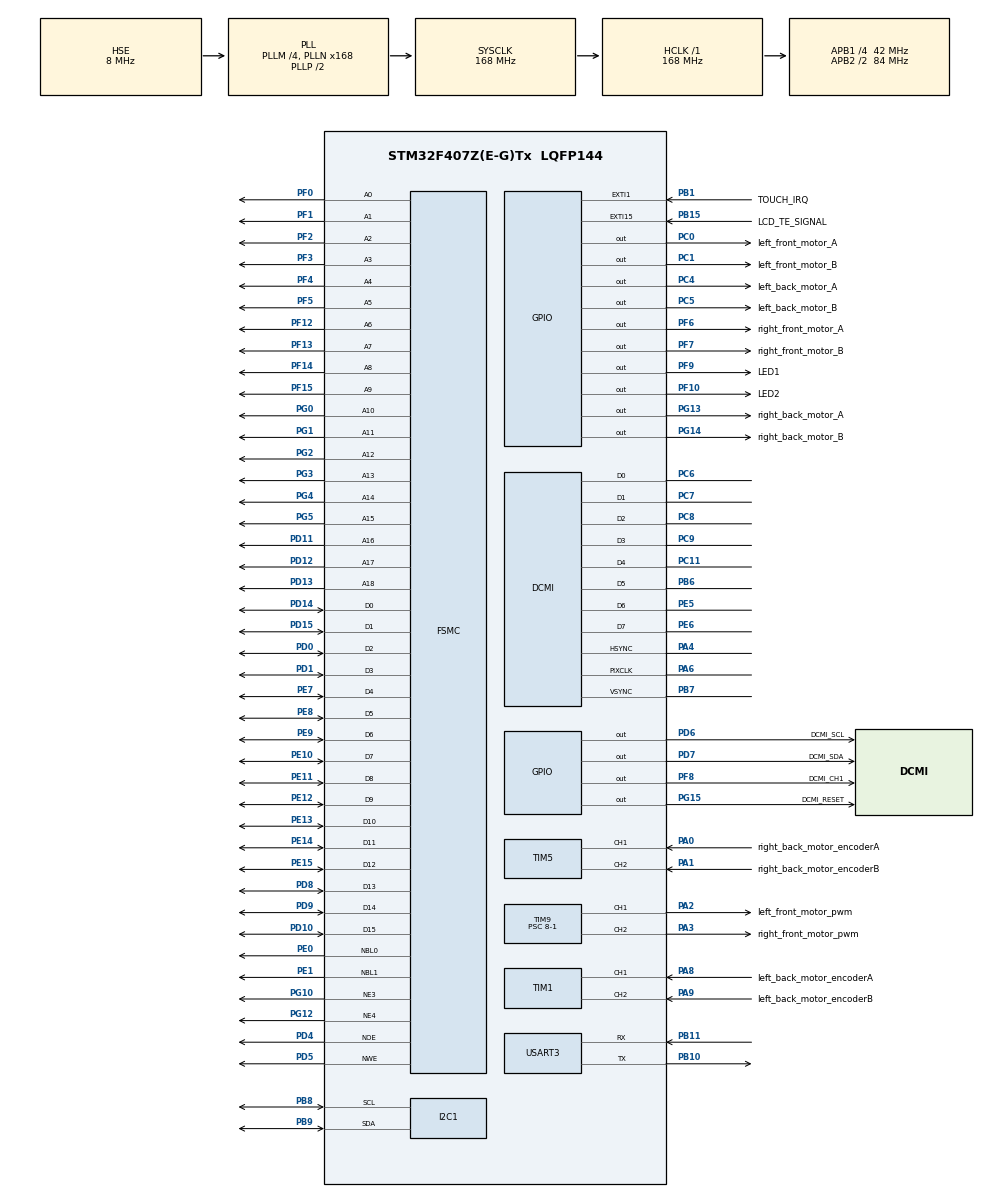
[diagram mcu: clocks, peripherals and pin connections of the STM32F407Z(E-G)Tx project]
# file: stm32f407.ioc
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DCMI.PCKPolarity=DCMI_PCKPOLARITY_RISING
DCMI.VSPolarity=DCMI_VSPOLARITY_LOW
Dma.DCMI.0.Direction=DMA_PERIPH_TO_MEMORY
Dma.DCMI.0.FIFOMode=DMA_FIFOMODE_ENABLE
Dma.DCMI.0.FIFOThreshold=DMA_FIFO_THRESHOLD_FULL
Dma.DCMI.0.Instance=DMA2_Stream1
Dma.DCMI.0.MemBurst=DMA_MBURST_SINGLE
Dma.DCMI.0.MemDataAlignment=DMA_MDATAALIGN_HALFWORD
Dma.DCMI.0.MemInc=DMA_MINC_DISABLE
Dma.DCMI.0.Mode=DMA_CIRCULAR
Dma.DCMI.0.PeriphBurst=DMA_PBURST_SINGLE
Dma.DCMI.0.PeriphDataAlignment=DMA_PDATAALIGN_WORD
Dma.DCMI.0.PeriphInc=DMA_PINC_DISABLE
Dma.DCMI.0.Priority=DMA_PRIORITY_HIGH
Dma.MEMTOMEM.1.Direction=DMA_MEMORY_TO_MEMORY
Dma.MEMTOMEM.1.FIFOMode=DMA_FIFOMODE_ENABLE
Dma.MEMTOMEM.1.FIFOThreshold=DMA_FIFO_THRESHOLD_FULL
Dma.MEMTOMEM.1.Instance=DMA2_Stream0
Dma.MEMTOMEM.1.MemBurst=DMA_MBURST_SINGLE
Dma.MEMTOMEM.1.MemDataAlignment=DMA_MDATAALIGN_HALFWORD
Dma.MEMTOMEM.1.MemInc=DMA_MINC_DISABLE
Dma.MEMTOMEM.1.Mode=DMA_NORMAL
Dma.MEMTOMEM.1.PeriphBurst=DMA_PBURST_SINGLE
Dma.MEMTOMEM.1.PeriphDataAlignment=DMA_PDATAALIGN_HALFWORD
Dma.MEMTOMEM.1.PeriphInc=DMA_PINC_ENABLE
Dma.MEMTOMEM.1.Priority=DMA_PRIORITY_HIGH
Dma.Request0=DCMI
Dma.Request1=MEMTOMEM
FREERTOS.BinarySemaphores01=touchSignal,Static,touchSignalControlBlock
FREERTOS.Queues01=mid_MsgQueue,2,touchDataDef,0,Static,mid_MsgQueueBuffer,mid_MsgQueueControlBlock
FREERTOS.Tasks01=defaultTask,0,128,StartDefaultTask,Default,NULL,Dynamic,NULL,NULL;GUITask,0,4096,StartGUITask,Default,NULL,Static,GUITaskBuffer,GUITaskControlBlock
FREERTOS.configIDLE_SHOULD_YIELD=0
FREERTOS.configUSE_APPLICATION_TASK_TAG=0
FREERTOS.configUSE_NEWLIB_REENTRANT=1
FSMC.AddressSetupTime1=5
FSMC.AddressSetupTime2=2
FSMC.BusTurnAroundDuration1=1
FSMC.BusTurnAroundDuration2=1
FSMC.DataSetupTime1=7
FSMC.DataSetupTime2=2
FSMC.ExtendedMode1=FSMC_EXTENDED_MODE_DISABLE
FSMC.WriteOperation1=FSMC_WRITE_OPERATION_ENABLE
Mcu.Family=STM32F4
Mcu.Name=STM32F407Z(E-G)Tx
Mcu.Package=LQFP144
NVIC.DCMI_IRQn=true\:5\:0\:false\:false\:true\:true\:true\:true
NVIC.DMA2_Stream1_IRQn=true\:5\:0\:false\:false\:true\:true\:false\:true
NVIC.EXTI15_10_IRQn=true\:5\:0\:false\:false\:true\:true\:true\:true
NVIC.EXTI1_IRQn=true\:5\:0\:false\:false\:true\:true\:true\:true
NVIC.PriorityGroup=NVIC_PRIORITYGROUP_4
NVIC.TIM6_DAC_IRQn=true\:15\:0\:false\:false\:true\:false\:false\:true
NVIC.TimeBase=TIM6_DAC_IRQn
NVIC.TimeBaseIP=TIM6
PA0-WKUP.GPIO_Label=right_back_motor_encoderA
PA0-WKUP.GPIO_Speed=GPIO_SPEED_FREQ_VERY_HIGH
PA0-WKUP.Signal=S_TIM5_CH1
PA1.GPIO_Label=right_back_motor_encoderB
PA1.GPIO_Speed=GPIO_SPEED_FREQ_VERY_HIGH
PA1.Signal=S_TIM5_CH2
PA13.Mode=Serial_Wire
PA13.Signal=SYS_JTMS-SWDIO
PA14.Mode=Serial_Wire
PA14.Signal=SYS_JTCK-SWCLK
PA2.GPIO_Label=left_front_motor_pwm
PA2.GPIO_Speed=GPIO_SPEED_FREQ_VERY_HIGH
PA2.Signal=S_TIM9_CH1
PA3.GPIO_Label=right_front_motor_pwm
PA3.GPIO_Speed=GPIO_SPEED_FREQ_VERY_HIGH
PA3.Signal=S_TIM9_CH2
PA4.Mode=Slave_8_bits_External_Synchro
PA4.Signal=DCMI_HSYNC
PA6.Mode=Slave_8_bits_External_Synchro
PA6.Signal=DCMI_PIXCLK
PA8.GPIO_Label=left_back_motor_encoderA
PA8.Signal=S_TIM1_CH1
PA9.GPIO_Label=left_back_motor_encoderB
PA9.Signal=S_TIM1_CH2
PB1.GPIO_Label=TOUCH_IRQ
PB1.GPIO_ModeDefaultEXTI=GPIO_MODE_IT_FALLING
PB1.GPIO_PuPd=GPIO_PULLUP
PB1.Signal=GPXTI1
PB10.Mode=Asynchronous
PB10.Signal=USART3_TX
PB11.Mode=Asynchronous
PB11.Signal=USART3_RX
PB15.GPIO_Label=LCD_TE_SIGNAL
PB15.GPIO_ModeDefaultEXTI=GPIO_MODE_IT_RISING
PB15.Signal=GPXTI15
PB3.Signal=SPI1_SCK
PB4.Signal=SPI1_MISO
PB5.Signal=SPI1_MOSI
PB6.Mode=Slave_8_bits_External_Synchro
PB6.Signal=DCMI_D5
PB7.Mode=Slave_8_bits_External_Synchro
PB7.Signal=DCMI_VSYNC
PB8.GPIO_Pu=GPIO_PULLUP
PB8.Mode=I2C
PB8.Signal=I2C1_SCL
PB9.GPIO_Pu=GPIO_PULLUP
PB9.Mode=I2C
PB9.Signal=I2C1_SDA
PC0.GPIO_Label=left_front_motor_A
PC0.GPIO_Speed=GPIO_SPEED_FREQ_HIGH
PC0.Signal=GPIO_Output
PC1.GPIO_Label=left_front_motor_B
PC1.GPIO_Speed=GPIO_SPEED_FREQ_HIGH
PC1.Signal=GPIO_Output
PC11.Mode=Slave_8_bits_External_Synchro
PC11.Signal=DCMI_D4
PC14-OSC32_IN.Mode=LSE-External-Oscillator
PC14-OSC32_IN.Signal=RCC_OSC32_IN
PC15-OSC32_OUT.Mode=LSE-External-Oscillator
PC15-OSC32_OUT.Signal=RCC_OSC32_OUT
PC4.GPIO_Label=left_back_motor_A
PC4.GPIO_Speed=GPIO_SPEED_FREQ_HIGH
PC4.Signal=GPIO_Output
PC5.GPIO_Label=left_back_motor_B
PC5.GPIO_Speed=GPIO_SPEED_FREQ_HIGH
PC5.Signal=GPIO_Output
PC6.Mode=Slave_8_bits_External_Synchro
PC6.Signal=DCMI_D0
PC7.Mode=Slave_8_bits_External_Synchro
PC7.Signal=DCMI_D1
PC8.Mode=Slave_8_bits_External_Synchro
PC8.Signal=DCMI_D2
PC9.Mode=Slave_8_bits_External_Synchro
PC9.Signal=DCMI_D3
PD0.Signal=FSMC_D2_DA2
PD1.Signal=FSMC_D3_DA3
PD10.Signal=FSMC_D15_DA15
PD11.Signal=FSMC_A16_CLE
PD12.Signal=FSMC_A17_ALE
PD13.Signal=FSMC_A18
PD14.Signal=FSMC_D0_DA0
PD15.Signal=FSMC_D1_DA1
PD4.Signal=FSMC_NOE
PD5.Signal=FSMC_NWE
PD6.GPIO_Label=DCMI_SCL
PD6.GPIO_ModeDefaultOutputPP=GPIO_MODE_OUTPUT_OD
PD6.GPIO_Speed=GPIO_SPEED_FREQ_VERY_HIGH
PD6.PinState=GPIO_PIN_SET
PD6.Signal=GPIO_Output
PD7.GPIO_Label=DCMI_SDA
PD7.GPIO_ModeDefaultOutputPP=GPIO_MODE_OUTPUT_OD
PD7.GPIO_Speed=GPIO_SPEED_FREQ_VERY_HIGH
PD7.PinState=GPIO_PIN_SET
PD7.Signal=GPIO_Output
PD8.Signal=FSMC_D13_DA13
PD9.Signal=FSMC_D14_DA14
PE0.Signal=FSMC_NBL0
PE1.Signal=FSMC_NBL1
PE10.Signal=FSMC_D7_DA7
PE11.Signal=FSMC_D8_DA8
PE12.Signal=FSMC_D9_DA9
PE13.Signal=FSMC_D10_DA10
PE14.Signal=FSMC_D11_DA11
PE15.Signal=FSMC_D12_DA12
PE5.Mode=Slave_8_bits_External_Synchro
PE5.Signal=DCMI_D6
PE6.Mode=Slave_8_bits_External_Synchro
PE6.Signal=DCMI_D7
PE7.Signal=FSMC_D4_DA4
PE8.Signal=FSMC_D5_DA5
PE9.Signal=FSMC_D6_DA6
PF0.Signal=FSMC_A0
PF1.Signal=FSMC_A1
PF10.GPIO_Label=LED2
PF10.PinState=GPIO_PIN_SET
PF10.Signal=GPIO_Output
PF12.Signal=FSMC_A6
PF13.Signal=FSMC_A7
PF14.Signal=FSMC_A8
PF15.Signal=FSMC_A9
PF2.Signal=FSMC_A2
PF3.Signal=FSMC_A3
PF4.Signal=FSMC_A4
PF5.Signal=FSMC_A5
PF6.GPIO_Label=right_front_motor_A
PF6.GPIO_Speed=GPIO_SPEED_FREQ_HIGH
PF6.Signal=GPIO_Output
PF7.GPIO_Label=right_front_motor_B
PF7.GPIO_Speed=GPIO_SPEED_FREQ_HIGH
PF7.Signal=GPIO_Output
PF8.GPIO_Label=DCMI_CH1
PF8.Signal=GPIO_Output
PF9.GPIO_Label=LED1
PF9.PinState=GPIO_PIN_SET
PF9.Signal=GPIO_Output
PG0.Signal=FSMC_A10
PG1.Signal=FSMC_A11
PG10.Mode=NorPsramChipSelect3_1
PG10.Signal=FSMC_NE3
PG12.Mode=NorPsramChipSelect4_2
PG12.Signal=FSMC_NE4
PG13.GPIO_Label=right_back_motor_A
PG13.GPIO_Speed=GPIO_SPEED_FREQ_HIGH
PG13.Signal=GPIO_Output
PG14.GPIO_Label=right_back_motor_B
PG14.GPIO_Speed=GPIO_SPEED_FREQ_HIGH
PG14.Signal=GPIO_Output
PG15.GPIO_Label=DCMI_RESET
PG15.Signal=GPIO_Output
PG2.Signal=FSMC_A12
PG3.Signal=FSMC_A13
PG4.Signal=FSMC_A14
PG5.Signal=FSMC_A15
PH0-OSC_IN.Mode=HSE-External-Oscillator
PH0-OSC_IN.Signal=RCC_OSC_IN
PH1-OSC_OUT.Mode=HSE-External-Oscillator
PH1-OSC_OUT.Signal=RCC_OSC_OUT
ProjectManager.HeapSize=0x200
ProjectManager.StackSize=0x1000
ProjectManager.TargetToolchain=STM32CubeIDE
RCC.48MHZClocksFreq_Value=84000000
RCC.AHBFreq_Value=168000000
RCC.APB1CLKDivider=RCC_HCLK_DIV4
RCC.APB1Freq_Value=42000000
RCC.APB1TimFreq_Value=84000000
RCC.APB2CLKDivider=RCC_HCLK_DIV2
RCC.APB2Freq_Value=84000000
RCC.APB2TimFreq_Value=168000000
RCC.CortexFreq_Value=168000000
RCC.HCLKFreq_Value=168000000
RCC.HSE_VALUE=8000000
RCC.HSI_VALUE=16000000
RCC.PLLM=4
RCC.PLLN=168
RCC.PLLSourceVirtual=RCC_PLLSOURCE_HSE
RCC.RCC_RTC_Clock_SourceVirtual=RCC_RTCCLKSOURCE_LSE
RCC.SYSCLKFreq_VALUE=168000000
RCC.SYSCLKSource=RCC_SYSCLKSOURCE_PLLCLK
RCC.VCOOutputFreq_Value=336000000
RTC.Date=1
RTC.Format=RTC_FORMAT_BIN
RTC.Hours=10
RTC.Month=RTC_MONTH_JANUARY
RTC.WeekDay=RTC_WEEKDAY_MONDAY
RTC.Year=21
SH.FSMC_A0.0=FSMC_A0,19b-a1
SH.FSMC_A1.0=FSMC_A1,19b-a1
SH.FSMC_A10.0=FSMC_A10,19b-a1
SH.FSMC_A11.0=FSMC_A11,19b-a1
SH.FSMC_A12.0=FSMC_A12,19b-a1
SH.FSMC_A13.0=FSMC_A13,19b-a1
SH.FSMC_A14.0=FSMC_A14,19b-a1
SH.FSMC_A15.0=FSMC_A15,19b-a1
SH.FSMC_A16_CLE.0=FSMC_A16,19b-a1
SH.FSMC_A17_ALE.0=FSMC_A17,19b-a1
SH.FSMC_A18.0=FSMC_A18,19b-a1
SH.FSMC_A2.0=FSMC_A2,19b-a1
SH.FSMC_A3.0=FSMC_A3,19b-a1
SH.FSMC_A4.0=FSMC_A4,19b-a1
SH.FSMC_A5.0=FSMC_A5,19b-a1
SH.FSMC_A6.0=FSMC_A6,19b-a1
SH.FSMC_A6.1=FSMC_A6,A6_2
SH.FSMC_A7.0=FSMC_A7,19b-a1
SH.FSMC_A8.0=FSMC_A8,19b-a1
SH.FSMC_A9.0=FSMC_A9,19b-a1
SH.FSMC_D0_DA0.0=FSMC_D0,16b-d1
SH.FSMC_D0_DA0.1=FSMC_D0,16b-d2
SH.FSMC_D10_DA10.0=FSMC_D10,16b-d1
SH.FSMC_D10_DA10.1=FSMC_D10,16b-d2
SH.FSMC_D11_DA11.0=FSMC_D11,16b-d1
SH.FSMC_D11_DA11.1=FSMC_D11,16b-d2
SH.FSMC_D12_DA12.0=FSMC_D12,16b-d1
SH.FSMC_D12_DA12.1=FSMC_D12,16b-d2
SH.FSMC_D13_DA13.0=FSMC_D13,16b-d1
SH.FSMC_D13_DA13.1=FSMC_D13,16b-d2
SH.FSMC_D14_DA14.0=FSMC_D14,16b-d1
SH.FSMC_D14_DA14.1=FSMC_D14,16b-d2
SH.FSMC_D15_DA15.0=FSMC_D15,16b-d1
SH.FSMC_D15_DA15.1=FSMC_D15,16b-d2
SH.FSMC_D1_DA1.0=FSMC_D1,16b-d1
SH.FSMC_D1_DA1.1=FSMC_D1,16b-d2
SH.FSMC_D2_DA2.0=FSMC_D2,16b-d1
SH.FSMC_D2_DA2.1=FSMC_D2,16b-d2
SH.FSMC_D3_DA3.0=FSMC_D3,16b-d1
SH.FSMC_D3_DA3.1=FSMC_D3,16b-d2
SH.FSMC_D4_DA4.0=FSMC_D4,16b-d1
SH.FSMC_D4_DA4.1=FSMC_D4,16b-d2
SH.FSMC_D5_DA5.0=FSMC_D5,16b-d1
SH.FSMC_D5_DA5.1=FSMC_D5,16b-d2
SH.FSMC_D6_DA6.0=FSMC_D6,16b-d1
SH.FSMC_D6_DA6.1=FSMC_D6,16b-d2
SH.FSMC_D7_DA7.0=FSMC_D7,16b-d1
SH.FSMC_D7_DA7.1=FSMC_D7,16b-d2
SH.FSMC_D8_DA8.0=FSMC_D8,16b-d1
SH.FSMC_D8_DA8.1=FSMC_D8,16b-d2
SH.FSMC_D9_DA9.0=FSMC_D9,16b-d1
SH.FSMC_D9_DA9.1=FSMC_D9,16b-d2
SH.FSMC_NBL0.0=FSMC_NBL0,2ByteEnable1
SH.FSMC_NBL1.0=FSMC_NBL1,2ByteEnable1
SH.FSMC_NOE.0=FSMC_NOE,Sram1
SH.FSMC_NOE.1=FSMC_NOE,Lcd2
SH.FSMC_NWE.0=FSMC_NWE,Sram1
SH.FSMC_NWE.1=FSMC_NWE,Lcd2
SH.S_TIM1_CH1.0=TIM1_CH1,Encoder_Interface
SH.S_TIM1_CH2.0=TIM1_CH2,Encoder_Interface
SH.S_TIM5_CH1.0=TIM5_CH1,Encoder_Interface
SH.S_TIM5_CH2.0=TIM5_CH2,Encoder_Interface
SH.S_TIM9_CH1.0=TIM9_CH1,PWM Generation1 CH1
SH.S_TIM9_CH2.0=TIM9_CH2,PWM Generation2 CH2
STMicroelectronics.X-CUBE-TOUCHGFX.4.17.0.ApplicationCcGraphicsJjApplication=TouchGFXOoGenerator
STMicroelectronics.X-CUBE-TOUCHGFX.4.17.0.tgfx_address1=0x68000000
STMicroelectronics.X-CUBE-TOUCHGFX.4.17.0.tgfx_buffering_strategy=Single
STMicroelectronics.X-CUBE-TOUCHGFX.4.17.0.tgfx_custom_height=240
STMicroelectronics.X-CUBE-TOUCHGFX.4.17.0.tgfx_custom_width=400
STMicroelectronics.X-CUBE-TOUCHGFX.4.17.0.tgfx_datareader=Disabled
STMicroelectronics.X-CUBE-TOUCHGFX.4.17.0.tgfx_display_interface=disp_fmc
STMicroelectronics.X-CUBE-TOUCHGFX.4.17.0.tgfx_fmc_base_address=0x6000007E
STMicroelectronics.X-CUBE-TOUCHGFX.4.17.0.tgfx_location=By Address
STMicroelectronics.X-CUBE-TOUCHGFX.4.17.0_IsPackSelfContextualization=true
TIM5.EncoderMode=TIM_ENCODERMODE_TI12
TIM9.AutoReloadPreload=TIM_AUTORELOAD_PRELOAD_ENABLE
TIM9.Channel-PWM\ Generation1\ CH1=TIM_CHANNEL_1
TIM9.Channel-PWM\ Generation2\ CH2=TIM_CHANNEL_2
TIM9.Period=42000-1
TIM9.Prescaler=8-1
TIM9.Pulse-PWM\ Generation1\ CH1=21000-1
TIM9.Pulse-PWM\ Generation2\ CH2=21000-1
USART3.VirtualMode=VM_ASYNC
VP_CRC_VS_CRC.Mode=CRC_Activate
VP_FREERTOS_VS_CMSIS_V1.Mode=CMSIS_V1
VP_RTC_VS_RTC_Activate.Mode=RTC_Enabled
VP_RTC_VS_RTC_Calendar.Mode=RTC_Calendar
VP_STMicroelectronics.X-CUBE-TOUCHGFX_VS_GraphicsJjApplication_4.17.0.Mode=GraphicsJjApplication
VP_SYS_VS_tim6.Mode=TIM6
VP_TIM7_VS_ClockSourceINT.Mode=Enable_Timer
board=custom

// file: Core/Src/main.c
/* USER CODE BEGIN Header */
/**
  ******************************************************************************
  * @file           : main.c
  * @brief          : Main program body
  ******************************************************************************
  * @attention
  *
  * <h2><center>&copy; Copyright (c) 2021 STMicroelectronics.
  * All rights reserved.</center></h2>
  *
  * This software component is licensed by ST under BSD 3-Clause license,
  * the "License"; You may not use this file except in compliance with the
  * License. You may obtain a copy of the License at:
  *                        opensource.org/licenses/BSD-3-Clause
  *
  ******************************************************************************
  */
/* USER CODE END Header */
#include "main.h"
#include "cmsis_os.h"
#include "app_touchgfx.h"

/* USER CODE BEGIN Includes */
#include "print/Inc/print.h"
#include "Inc/mainpp.hpp"

/* USER CODE END Includes */

CRC_HandleTypeDef hcrc;

DCMI_HandleTypeDef hdcmi;
DMA_HandleTypeDef hdma_dcmi;

I2C_HandleTypeDef hi2c1;

RTC_HandleTypeDef hrtc;

TIM_HandleTypeDef htim1;
TIM_HandleTypeDef htim5;
TIM_HandleTypeDef htim7;
TIM_HandleTypeDef htim9;

UART_HandleTypeDef huart3;

DMA_HandleTypeDef hdma_memtomem_dma2_stream0;
SRAM_HandleTypeDef hsram1;
SRAM_HandleTypeDef hsram2;

osThreadId defaultTaskHandle;
osThreadId GUITaskHandle;
uint32_t GUITaskBuffer[ 4096 ];
osStaticThreadDef_t GUITaskControlBlock;
osMessageQId mid_MsgQueueHandle;
uint8_t mid_MsgQueueBuffer[ 2 * sizeof( touchDataDef ) ];
osStaticMessageQDef_t mid_MsgQueueControlBlock;
osSemaphoreId touchSignalHandle;
osStaticSemaphoreDef_t touchSignalControlBlock;
/* USER CODE BEGIN PV */
UART_HandleTypeDef *UartHandle = &huart3;
UART_HandleTypeDef *BluetoothUart = &huart3;
PWM_HandleTypeDef *left_front_motor_pwm = &htim9;
PWM_HandleTypeDef *right_front_motor_pwm = &htim9;
//PWM_HandleTypeDef *left_back_motor_pwm = &htim12;
//PWM_HandleTypeDef *right_back_motor_pwm = &htim12;
DCMI_HandleTypeDef *DCMI_Handle = &hdcmi;
I2C_HandleTypeDef *I2C_Handle = &hi2c1;
SRAM_HandleTypeDef *SRAM_Handle = &hsram1;
SRAM_HandleTypeDef *LCD_Handle = &hsram2;
DMA_HandleTypeDef *SRAMToLCD_DMA_Handle = &hdma_memtomem_dma2_stream0;
RTC_HandleTypeDef *RtcHandle = &hrtc;
/* USER CODE END PV */

void SystemClock_Config(void);
static void MX_GPIO_Init(void);
static void MX_TIM5_Init(void);
static void MX_FSMC_Init(void);
static void MX_TIM9_Init(void);
static void MX_DMA_Init(void);
static void MX_I2C1_Init(void);
static void MX_DCMI_Init(void);
static void MX_TIM7_Init(void);
static void MX_CRC_Init(void);
static void MX_TIM1_Init(void);
static void MX_USART3_UART_Init(void);
static void MX_RTC_Init(void);
void StartDefaultTask(void const * argument);
void StartGUITask(void const * argument);

int main(void)
{

  /* MCU Configuration--------------------------------------------------------*/

  /* Reset of all peripherals, Initializes the Flash interface and the Systick. */
  HAL_Init();

  /* Configure the system clock */
  SystemClock_Config();

  /* Initialize all configured peripherals */
  MX_GPIO_Init();
  MX_TIM5_Init();
  MX_FSMC_Init();
  MX_TIM9_Init();
  MX_DMA_Init();
  MX_I2C1_Init();
  MX_DCMI_Init();
  MX_TIM7_Init();
  MX_CRC_Init();
  MX_TIM1_Init();
  MX_USART3_UART_Init();
  MX_RTC_Init();
  MX_TouchGFX_Init();
  /* USER CODE BEGIN 2 */
    //printf("------stm32f407-----------\r\n");
    setup();

  /* USER CODE END 2 */

  /* Create the semaphores(s) */
  /* definition and creation of touchSignal */
  osSemaphoreStaticDef(touchSignal, &touchSignalControlBlock);
  touchSignalHandle = osSemaphoreCreate(osSemaphore(touchSignal), 1);

  /* Create the queue(s) */
  /* definition and creation of mid_MsgQueue */
  osMessageQStaticDef(mid_MsgQueue, 2, touchDataDef, mid_MsgQueueBuffer, &mid_MsgQueueControlBlock);
  mid_MsgQueueHandle = osMessageCreate(osMessageQ(mid_MsgQueue), NULL);

  /* Create the thread(s) */
  /* definition and creation of defaultTask */
  osThreadDef(defaultTask, StartDefaultTask, osPriorityNormal, 0, 128);
  defaultTaskHandle = osThreadCreate(osThread(defaultTask), NULL);

  /* definition and creation of GUITask */
  osThreadStaticDef(GUITask, StartGUITask, osPriorityNormal, 0, 4096, GUITaskBuffer, &GUITaskControlBlock);
  GUITaskHandle = osThreadCreate(osThread(GUITask), NULL);

  /* Start scheduler */
  osKernelStart();

  /* We should never get here as control is now taken by the scheduler */
  /* Infinite loop */
  /* USER CODE BEGIN WHILE */
    //Bluetooth_receiveData();
  while (1)
  {
      //loop();
      //Bluetooth_analysisRecData(Car_monitor);
    /* USER CODE END WHILE */

  }
}

void SystemClock_Config(void)
{
  RCC_OscInitTypeDef RCC_OscInitStruct = {0};
  RCC_ClkInitTypeDef RCC_ClkInitStruct = {0};

  /** Configure the main internal regulator output voltage
  */
  __HAL_RCC_PWR_CLK_ENABLE();
  __HAL_PWR_VOLTAGESCALING_CONFIG(PWR_REGULATOR_VOLTAGE_SCALE1);
  /** Initializes the RCC Oscillators according to the specified parameters
  * in the RCC_OscInitTypeDef structure.
  */
  RCC_OscInitStruct.OscillatorType = RCC_OSCILLATORTYPE_HSE|RCC_OSCILLATORTYPE_LSE;
  RCC_OscInitStruct.HSEState = RCC_HSE_ON;
  RCC_OscInitStruct.LSEState = RCC_LSE_ON;
  RCC_OscInitStruct.PLL.PLLState = RCC_PLL_ON;
  RCC_OscInitStruct.PLL.PLLSource = RCC_PLLSOURCE_HSE;
  RCC_OscInitStruct.PLL.PLLM = 4;
  RCC_OscInitStruct.PLL.PLLN = 168;
  RCC_OscInitStruct.PLL.PLLP = RCC_PLLP_DIV2;
  RCC_OscInitStruct.PLL.PLLQ = 4;
  if (HAL_RCC_OscConfig(&RCC_OscInitStruct) != HAL_OK)
  {
    Error_Handler();
  }
  /** Initializes the CPU, AHB and APB buses clocks
  */
  RCC_ClkInitStruct.ClockType = RCC_CLOCKTYPE_HCLK|RCC_CLOCKTYPE_SYSCLK
                              |RCC_CLOCKTYPE_PCLK1|RCC_CLOCKTYPE_PCLK2;
  RCC_ClkInitStruct.SYSCLKSource = RCC_SYSCLKSOURCE_PLLCLK;
  RCC_ClkInitStruct.AHBCLKDivider = RCC_SYSCLK_DIV1;
  RCC_ClkInitStruct.APB1CLKDivider = RCC_HCLK_DIV4;
  RCC_ClkInitStruct.APB2CLKDivider = RCC_HCLK_DIV2;

  if (HAL_RCC_ClockConfig(&RCC_ClkInitStruct, FLASH_LATENCY_5) != HAL_OK)
  {
    Error_Handler();
  }
}

static void MX_CRC_Init(void)
{

  hcrc.Instance = CRC;
  if (HAL_CRC_Init(&hcrc) != HAL_OK)
  {
    Error_Handler();
  }

}

static void MX_DCMI_Init(void)
{

  hdcmi.Instance = DCMI;
  hdcmi.Init.SynchroMode = DCMI_SYNCHRO_HARDWARE;
  hdcmi.Init.PCKPolarity = DCMI_PCKPOLARITY_RISING;
  hdcmi.Init.VSPolarity = DCMI_VSPOLARITY_LOW;
  hdcmi.Init.HSPolarity = DCMI_HSPOLARITY_LOW;
  hdcmi.Init.CaptureRate = DCMI_CR_ALL_FRAME;
  hdcmi.Init.ExtendedDataMode = DCMI_EXTEND_DATA_8B;
  hdcmi.Init.JPEGMode = DCMI_JPEG_DISABLE;
  if (HAL_DCMI_Init(&hdcmi) != HAL_OK)
  {
    Error_Handler();
  }

}

static void MX_I2C1_Init(void)
{

  hi2c1.Instance = I2C1;
  hi2c1.Init.ClockSpeed = 100000;
  hi2c1.Init.DutyCycle = I2C_DUTYCYCLE_2;
  hi2c1.Init.OwnAddress1 = 0;
  hi2c1.Init.AddressingMode = I2C_ADDRESSINGMODE_7BIT;
  hi2c1.Init.DualAddressMode = I2C_DUALADDRESS_DISABLE;
  hi2c1.Init.OwnAddress2 = 0;
  hi2c1.Init.GeneralCallMode = I2C_GENERALCALL_DISABLE;
  hi2c1.Init.NoStretchMode = I2C_NOSTRETCH_DISABLE;
  if (HAL_I2C_Init(&hi2c1) != HAL_OK)
  {
    Error_Handler();
  }

}

static void MX_RTC_Init(void)
{

  RTC_TimeTypeDef sTime = {0};
  RTC_DateTypeDef sDate = {0};

  /** Initialize RTC Only
  */
  hrtc.Instance = RTC;
  hrtc.Init.HourFormat = RTC_HOURFORMAT_24;
  hrtc.Init.AsynchPrediv = 127;
  hrtc.Init.SynchPrediv = 255;
  hrtc.Init.OutPut = RTC_OUTPUT_DISABLE;
  hrtc.Init.OutPutPolarity = RTC_OUTPUT_POLARITY_HIGH;
  hrtc.Init.OutPutType = RTC_OUTPUT_TYPE_OPENDRAIN;
  if (HAL_RTC_Init(&hrtc) != HAL_OK)
  {
    Error_Handler();
  }

  /* USER CODE BEGIN Check_RTC_BKUP */
  if(HAL_RTCEx_BKUPRead(&hrtc, RTC_BKP_DR0) != 0x32F2)
  {

  /* USER CODE END Check_RTC_BKUP */

  /** Initialize RTC and set the Time and Date
  */
  sTime.Hours = 10;
  sTime.Minutes = 0;
  sTime.Seconds = 0;
  sTime.DayLightSaving = RTC_DAYLIGHTSAVING_NONE;
  sTime.StoreOperation = RTC_STOREOPERATION_RESET;
  if (HAL_RTC_SetTime(&hrtc, &sTime, RTC_FORMAT_BIN) != HAL_OK)
  {
    Error_Handler();
  }
  sDate.WeekDay = RTC_WEEKDAY_MONDAY;
  sDate.Month = RTC_MONTH_JANUARY;
  sDate.Date = 1;
  sDate.Year = 21;

  if (HAL_RTC_SetDate(&hrtc, &sDate, RTC_FORMAT_BIN) != HAL_OK)
  {
    Error_Handler();
  }
  /* USER CODE BEGIN RTC_Init 2 */
    HAL_RTCEx_BKUPWrite(&hrtc,RTC_BKP_DR0,0x32F2);
  }
  else
  {
    /* Check if the Power On Reset flag is set */
    if(__HAL_RCC_GET_FLAG(RCC_FLAG_PORRST) != RESET)
    {
      /* Turn on LED2: Power on reset occurred */
      //BSP_LED_On(LED2);
    }
    /* Check if Pin Reset flag is set */
    if(__HAL_RCC_GET_FLAG(RCC_FLAG_PINRST) != RESET)
    {
      /* Turn on LED4: External reset occurred */
      //BSP_LED_On(LED4);
    }
    /* Clear source Reset Flag */
    __HAL_RCC_CLEAR_RESET_FLAGS();
  }

  /* USER CODE END RTC_Init 2 */

}

static void MX_TIM1_Init(void)
{

  TIM_Encoder_InitTypeDef sConfig = {0};
  TIM_MasterConfigTypeDef sMasterConfig = {0};

  htim1.Instance = TIM1;
  htim1.Init.Prescaler = 0;
  htim1.Init.CounterMode = TIM_COUNTERMODE_UP;
  htim1.Init.Period = 65535;
  htim1.Init.ClockDivision = TIM_CLOCKDIVISION_DIV1;
  htim1.Init.RepetitionCounter = 0;
  htim1.Init.AutoReloadPreload = TIM_AUTORELOAD_PRELOAD_DISABLE;
  sConfig.EncoderMode = TIM_ENCODERMODE_TI1;
  sConfig.IC1Polarity = TIM_ICPOLARITY_RISING;
  sConfig.IC1Selection = TIM_ICSELECTION_DIRECTTI;
  sConfig.IC1Prescaler = TIM_ICPSC_DIV1;
  sConfig.IC1Filter = 0;
  sConfig.IC2Polarity = TIM_ICPOLARITY_RISING;
  sConfig.IC2Selection = TIM_ICSELECTION_DIRECTTI;
  sConfig.IC2Prescaler = TIM_ICPSC_DIV1;
  sConfig.IC2Filter = 0;
  if (HAL_TIM_Encoder_Init(&htim1, &sConfig) != HAL_OK)
  {
    Error_Handler();
  }
  sMasterConfig.MasterOutputTrigger = TIM_TRGO_RESET;
  sMasterConfig.MasterSlaveMode = TIM_MASTERSLAVEMODE_DISABLE;
  if (HAL_TIMEx_MasterConfigSynchronization(&htim1, &sMasterConfig) != HAL_OK)
  {
    Error_Handler();
  }

}

static void MX_TIM5_Init(void)
{

  TIM_Encoder_InitTypeDef sConfig = {0};
  TIM_MasterConfigTypeDef sMasterConfig = {0};

  htim5.Instance = TIM5;
  htim5.Init.Prescaler = 0;
  htim5.Init.CounterMode = TIM_COUNTERMODE_UP;
  htim5.Init.Period = 4294967295;
  htim5.Init.ClockDivision = TIM_CLOCKDIVISION_DIV1;
  htim5.Init.AutoReloadPreload = TIM_AUTORELOAD_PRELOAD_DISABLE;
  sConfig.EncoderMode = TIM_ENCODERMODE_TI12;
  sConfig.IC1Polarity = TIM_ICPOLARITY_RISING;
  sConfig.IC1Selection = TIM_ICSELECTION_DIRECTTI;
  sConfig.IC1Prescaler = TIM_ICPSC_DIV1;
  sConfig.IC1Filter = 0;
  sConfig.IC2Polarity = TIM_ICPOLARITY_RISING;
  sConfig.IC2Selection = TIM_ICSELECTION_DIRECTTI;
  sConfig.IC2Prescaler = TIM_ICPSC_DIV1;
  sConfig.IC2Filter = 0;
  if (HAL_TIM_Encoder_Init(&htim5, &sConfig) != HAL_OK)
  {
    Error_Handler();
  }
  sMasterConfig.MasterOutputTrigger = TIM_TRGO_RESET;
  sMasterConfig.MasterSlaveMode = TIM_MASTERSLAVEMODE_DISABLE;
  if (HAL_TIMEx_MasterConfigSynchronization(&htim5, &sMasterConfig) != HAL_OK)
  {
    Error_Handler();
  }

}

static void MX_TIM7_Init(void)
{

  TIM_MasterConfigTypeDef sMasterConfig = {0};

  htim7.Instance = TIM7;
  htim7.Init.Prescaler = 0;
  htim7.Init.CounterMode = TIM_COUNTERMODE_UP;
  htim7.Init.Period = 65535;
  htim7.Init.AutoReloadPreload = TIM_AUTORELOAD_PRELOAD_DISABLE;
  if (HAL_TIM_Base_Init(&htim7) != HAL_OK)
  {
    Error_Handler();
  }
  sMasterConfig.MasterOutputTrigger = TIM_TRGO_RESET;
  sMasterConfig.MasterSlaveMode = TIM_MASTERSLAVEMODE_DISABLE;
  if (HAL_TIMEx_MasterConfigSynchronization(&htim7, &sMasterConfig) != HAL_OK)
  {
    Error_Handler();
  }

}

static void MX_TIM9_Init(void)
{

  TIM_OC_InitTypeDef sConfigOC = {0};

  htim9.Instance = TIM9;
  htim9.Init.Prescaler = 8-1;
  htim9.Init.CounterMode = TIM_COUNTERMODE_UP;
  htim9.Init.Period = 42000-1;
  htim9.Init.ClockDivision = TIM_CLOCKDIVISION_DIV1;
  htim9.Init.AutoReloadPreload = TIM_AUTORELOAD_PRELOAD_ENABLE;
  if (HAL_TIM_PWM_Init(&htim9) != HAL_OK)
  {
    Error_Handler();
  }
  sConfigOC.OCMode = TIM_OCMODE_PWM1;
  sConfigOC.Pulse = 21000-1;
  sConfigOC.OCPolarity = TIM_OCPOLARITY_HIGH;
  sConfigOC.OCFastMode = TIM_OCFAST_DISABLE;
  if (HAL_TIM_PWM_ConfigChannel(&htim9, &sConfigOC, TIM_CHANNEL_1) != HAL_OK)
  {
    Error_Handler();
  }
  if (HAL_TIM_PWM_ConfigChannel(&htim9, &sConfigOC, TIM_CHANNEL_2) != HAL_OK)
  {
    Error_Handler();
  }
  HAL_TIM_MspPostInit(&htim9);

}

static void MX_USART3_UART_Init(void)
{

  huart3.Instance = USART3;
  huart3.Init.BaudRate = 115200;
  huart3.Init.WordLength = UART_WORDLENGTH_8B;
  huart3.Init.StopBits = UART_STOPBITS_1;
  huart3.Init.Parity = UART_PARITY_NONE;
  huart3.Init.Mode = UART_MODE_TX_RX;
  huart3.Init.HwFlowCtl = UART_HWCONTROL_NONE;
  huart3.Init.OverSampling = UART_OVERSAMPLING_16;
  if (HAL_UART_Init(&huart3) != HAL_OK)
  {
    Error_Handler();
  }

}

static void MX_DMA_Init(void)
{

  /* DMA controller clock enable */
  __HAL_RCC_DMA2_CLK_ENABLE();

  /* Configure DMA request hdma_memtomem_dma2_stream0 on DMA2_Stream0 */
  hdma_memtomem_dma2_stream0.Instance = DMA2_Stream0;
  hdma_memtomem_dma2_stream0.Init.Channel = DMA_CHANNEL_0;
  hdma_memtomem_dma2_stream0.Init.Direction = DMA_MEMORY_TO_MEMORY;
  hdma_memtomem_dma2_stream0.Init.PeriphInc = DMA_PINC_ENABLE;
  hdma_memtomem_dma2_stream0.Init.MemInc = DMA_MINC_DISABLE;
  hdma_memtomem_dma2_stream0.Init.PeriphDataAlignment = DMA_PDATAALIGN_HALFWORD;
  hdma_memtomem_dma2_stream0.Init.MemDataAlignment = DMA_MDATAALIGN_HALFWORD;
  hdma_memtomem_dma2_stream0.Init.Mode = DMA_NORMAL;
  hdma_memtomem_dma2_stream0.Init.Priority = DMA_PRIORITY_HIGH;
  hdma_memtomem_dma2_stream0.Init.FIFOMode = DMA_FIFOMODE_ENABLE;
  hdma_memtomem_dma2_stream0.Init.FIFOThreshold = DMA_FIFO_THRESHOLD_FULL;
  hdma_memtomem_dma2_stream0.Init.MemBurst = DMA_MBURST_SINGLE;
  hdma_memtomem_dma2_stream0.Init.PeriphBurst = DMA_PBURST_SINGLE;
  if (HAL_DMA_Init(&hdma_memtomem_dma2_stream0) != HAL_OK)
  {
    Error_Handler( );
  }

  /* DMA interrupt init */
  /* DMA2_Stream1_IRQn interrupt configuration */
  HAL_NVIC_SetPriority(DMA2_Stream1_IRQn, 5, 0);
  HAL_NVIC_EnableIRQ(DMA2_Stream1_IRQn);

}

static void MX_GPIO_Init(void)
{
  GPIO_InitTypeDef GPIO_InitStruct = {0};

  /* GPIO Ports Clock Enable */
  __HAL_RCC_GPIOE_CLK_ENABLE();
  __HAL_RCC_GPIOC_CLK_ENABLE();
  __HAL_RCC_GPIOF_CLK_ENABLE();
  __HAL_RCC_GPIOH_CLK_ENABLE();
  __HAL_RCC_GPIOA_CLK_ENABLE();
  __HAL_RCC_GPIOB_CLK_ENABLE();
  __HAL_RCC_GPIOG_CLK_ENABLE();
  __HAL_RCC_GPIOD_CLK_ENABLE();

  /*Configure GPIO pin Output Level */
  HAL_GPIO_WritePin(GPIOF, right_front_motor_A_Pin|right_front_motor_B_Pin|DCMI_CH1_Pin, GPIO_PIN_RESET);

  /*Configure GPIO pin Output Level */
  HAL_GPIO_WritePin(GPIOF, LED1_Pin|LED2_Pin, GPIO_PIN_SET);

  /*Configure GPIO pin Output Level */
  HAL_GPIO_WritePin(GPIOC, left_front_motor_A_Pin|left_front_motor_B_Pin|left_back_motor_A_Pin|left_back_motor_B_Pin, GPIO_PIN_RESET);

  /*Configure GPIO pin Output Level */
  HAL_GPIO_WritePin(GPIOD, DCMI_SCL_Pin|DCMI_SDA_Pin, GPIO_PIN_SET);

  /*Configure GPIO pin Output Level */
  HAL_GPIO_WritePin(GPIOG, right_back_motor_A_Pin|right_back_motor_B_Pin|DCMI_RESET_Pin, GPIO_PIN_RESET);

  /*Configure GPIO pins : right_front_motor_A_Pin right_front_motor_B_Pin */
  GPIO_InitStruct.Pin = right_front_motor_A_Pin|right_front_motor_B_Pin;
  GPIO_InitStruct.Mode = GPIO_MODE_OUTPUT_PP;
  GPIO_InitStruct.Pull = GPIO_NOPULL;
  GPIO_InitStruct.Speed = GPIO_SPEED_FREQ_HIGH;
  HAL_GPIO_Init(GPIOF, &GPIO_InitStruct);

  /*Configure GPIO pins : DCMI_CH1_Pin LED1_Pin LED2_Pin */
  GPIO_InitStruct.Pin = DCMI_CH1_Pin|LED1_Pin|LED2_Pin;
  GPIO_InitStruct.Mode = GPIO_MODE_OUTPUT_PP;
  GPIO_InitStruct.Pull = GPIO_NOPULL;
  GPIO_InitStruct.Speed = GPIO_SPEED_FREQ_LOW;
  HAL_GPIO_Init(GPIOF, &GPIO_InitStruct);

  /*Configure GPIO pins : left_front_motor_A_Pin left_front_motor_B_Pin left_back_motor_A_Pin left_back_motor_B_Pin */
  GPIO_InitStruct.Pin = left_front_motor_A_Pin|left_front_motor_B_Pin|left_back_motor_A_Pin|left_back_motor_B_Pin;
  GPIO_InitStruct.Mode = GPIO_MODE_OUTPUT_PP;
  GPIO_InitStruct.Pull = GPIO_NOPULL;
  GPIO_InitStruct.Speed = GPIO_SPEED_FREQ_HIGH;
  HAL_GPIO_Init(GPIOC, &GPIO_InitStruct);

  /*Configure GPIO pin : TOUCH_IRQ_Pin */
  GPIO_InitStruct.Pin = TOUCH_IRQ_Pin;
  GPIO_InitStruct.Mode = GPIO_MODE_IT_FALLING;
  GPIO_InitStruct.Pull = GPIO_PULLUP;
  HAL_GPIO_Init(TOUCH_IRQ_GPIO_Port, &GPIO_InitStruct);

  /*Configure GPIO pin : LCD_TE_SIGNAL_Pin */
  GPIO_InitStruct.Pin = LCD_TE_SIGNAL_Pin;
  GPIO_InitStruct.Mode = GPIO_MODE_IT_RISING;
  GPIO_InitStruct.Pull = GPIO_NOPULL;
  HAL_GPIO_Init(LCD_TE_SIGNAL_GPIO_Port, &GPIO_InitStruct);

  /*Configure GPIO pins : DCMI_SCL_Pin DCMI_SDA_Pin */
  GPIO_InitStruct.Pin = DCMI_SCL_Pin|DCMI_SDA_Pin;
  GPIO_InitStruct.Mode = GPIO_MODE_OUTPUT_OD;
  GPIO_InitStruct.Pull = GPIO_NOPULL;
  GPIO_InitStruct.Speed = GPIO_SPEED_FREQ_VERY_HIGH;
  HAL_GPIO_Init(GPIOD, &GPIO_InitStruct);

  /*Configure GPIO pins : right_back_motor_A_Pin right_back_motor_B_Pin */
  GPIO_InitStruct.Pin = right_back_motor_A_Pin|right_back_motor_B_Pin;
  GPIO_InitStruct.Mode = GPIO_MODE_OUTPUT_PP;
  GPIO_InitStruct.Pull = GPIO_NOPULL;
  GPIO_InitStruct.Speed = GPIO_SPEED_FREQ_HIGH;
  HAL_GPIO_Init(GPIOG, &GPIO_InitStruct);

  /*Configure GPIO pin : DCMI_RESET_Pin */
  GPIO_InitStruct.Pin = DCMI_RESET_Pin;
  GPIO_InitStruct.Mode = GPIO_MODE_OUTPUT_PP;
  GPIO_InitStruct.Pull = GPIO_NOPULL;
  GPIO_InitStruct.Speed = GPIO_SPEED_FREQ_LOW;
  HAL_GPIO_Init(DCMI_RESET_GPIO_Port, &GPIO_InitStruct);

  /*Configure GPIO pins : PB3 PB4 PB5 */
  GPIO_InitStruct.Pin = GPIO_PIN_3|GPIO_PIN_4|GPIO_PIN_5;
  GPIO_InitStruct.Mode = GPIO_MODE_AF_PP;
  GPIO_InitStruct.Pull = GPIO_NOPULL;
  GPIO_InitStruct.Speed = GPIO_SPEED_FREQ_VERY_HIGH;
  GPIO_InitStruct.Alternate = GPIO_AF5_SPI1;
  HAL_GPIO_Init(GPIOB, &GPIO_InitStruct);

  /* EXTI interrupt init*/
  HAL_NVIC_SetPriority(EXTI1_IRQn, 5, 0);
  HAL_NVIC_EnableIRQ(EXTI1_IRQn);

  HAL_NVIC_SetPriority(EXTI15_10_IRQn, 5, 0);
  HAL_NVIC_EnableIRQ(EXTI15_10_IRQn);

}

/* FSMC initialization function */
static void MX_FSMC_Init(void)
{

  FSMC_NORSRAM_TimingTypeDef Timing = {0};

  /** Perform the SRAM1 memory initialization sequence
  */
  hsram1.Instance = FSMC_NORSRAM_DEVICE;
  hsram1.Extended = FSMC_NORSRAM_EXTENDED_DEVICE;
  /* hsram1.Init */
  hsram1.Init.NSBank = FSMC_NORSRAM_BANK3;
  hsram1.Init.DataAddressMux = FSMC_DATA_ADDRESS_MUX_DISABLE;
  hsram1.Init.MemoryType = FSMC_MEMORY_TYPE_SRAM;
  hsram1.Init.MemoryDataWidth = FSMC_NORSRAM_MEM_BUS_WIDTH_16;
  hsram1.Init.BurstAccessMode = FSMC_BURST_ACCESS_MODE_DISABLE;
  hsram1.Init.WaitSignalPolarity = FSMC_WAIT_SIGNAL_POLARITY_LOW;
  hsram1.Init.WrapMode = FSMC_WRAP_MODE_DISABLE;
  hsram1.Init.WaitSignalActive = FSMC_WAIT_TIMING_BEFORE_WS;
  hsram1.Init.WriteOperation = FSMC_WRITE_OPERATION_ENABLE;
  hsram1.Init.WaitSignal = FSMC_WAIT_SIGNAL_DISABLE;
  hsram1.Init.ExtendedMode = FSMC_EXTENDED_MODE_DISABLE;
  hsram1.Init.AsynchronousWait = FSMC_ASYNCHRONOUS_WAIT_DISABLE;
  hsram1.Init.WriteBurst = FSMC_WRITE_BURST_DISABLE;
  hsram1.Init.PageSize = FSMC_PAGE_SIZE_NONE;
  /* Timing */
  Timing.AddressSetupTime = 5;
  Timing.AddressHoldTime = 15;
  Timing.DataSetupTime = 7;
  Timing.BusTurnAroundDuration = 1;
  Timing.CLKDivision = 16;
  Timing.DataLatency = 17;
  Timing.AccessMode = FSMC_ACCESS_MODE_A;
  /* ExtTiming */

  if (HAL_SRAM_Init(&hsram1, &Timing, NULL) != HAL_OK)
  {
    Error_Handler( );
  }

  /** Perform the SRAM2 memory initialization sequence
  */
  hsram2.Instance = FSMC_NORSRAM_DEVICE;
  hsram2.Extended = FSMC_NORSRAM_EXTENDED_DEVICE;
  /* hsram2.Init */
  hsram2.Init.NSBank = FSMC_NORSRAM_BANK4;
  hsram2.Init.DataAddressMux = FSMC_DATA_ADDRESS_MUX_DISABLE;
  hsram2.Init.MemoryType = FSMC_MEMORY_TYPE_SRAM;
  hsram2.Init.MemoryDataWidth = FSMC_NORSRAM_MEM_BUS_WIDTH_16;
  hsram2.Init.BurstAccessMode = FSMC_BURST_ACCESS_MODE_DISABLE;
  hsram2.Init.WaitSignalPolarity = FSMC_WAIT_SIGNAL_POLARITY_LOW;
  hsram2.Init.WrapMode = FSMC_WRAP_MODE_DISABLE;
  hsram2.Init.WaitSignalActive = FSMC_WAIT_TIMING_BEFORE_WS;
  hsram2.Init.WriteOperation = FSMC_WRITE_OPERATION_ENABLE;
  hsram2.Init.WaitSignal = FSMC_WAIT_SIGNAL_DISABLE;
  hsram2.Init.ExtendedMode = FSMC_EXTENDED_MODE_DISABLE;
  hsram2.Init.AsynchronousWait = FSMC_ASYNCHRONOUS_WAIT_DISABLE;
  hsram2.Init.WriteBurst = FSMC_WRITE_BURST_DISABLE;
  hsram2.Init.PageSize = FSMC_PAGE_SIZE_NONE;
  /* Timing */
  Timing.AddressSetupTime = 2;
  Timing.AddressHoldTime = 15;
  Timing.DataSetupTime = 2;
  Timing.BusTurnAroundDuration = 1;
  Timing.CLKDivision = 16;
  Timing.DataLatency = 17;
  Timing.AccessMode = FSMC_ACCESS_MODE_A;
  /* ExtTiming */

  if (HAL_SRAM_Init(&hsram2, &Timing, NULL) != HAL_OK)
  {
    Error_Handler( );
  }

}

void StartDefaultTask(void const * argument)
{
  /* USER CODE BEGIN 5 */
  /* Infinite loop */
  for(;;)
  {
	  loop();
  }
  /* USER CODE END 5 */
}

void StartGUITask(void const * argument)
{
  /* USER CODE BEGIN StartGUITask */
    MX_TouchGFX_Process();
  /* Infinite loop */
  for(;;)
  {
    osDelay(10);
  }
  /* USER CODE END StartGUITask */
}

void HAL_TIM_PeriodElapsedCallback(TIM_HandleTypeDef *htim)
{
  if (htim->Instance == TIM6) {
    HAL_IncTick();
  }
}

void Error_Handler(void)
{
  __disable_irq();
  while (1)
  {
  }
}

/************************ (C) COPYRIGHT STMicroelectronics *****END OF FILE****/
